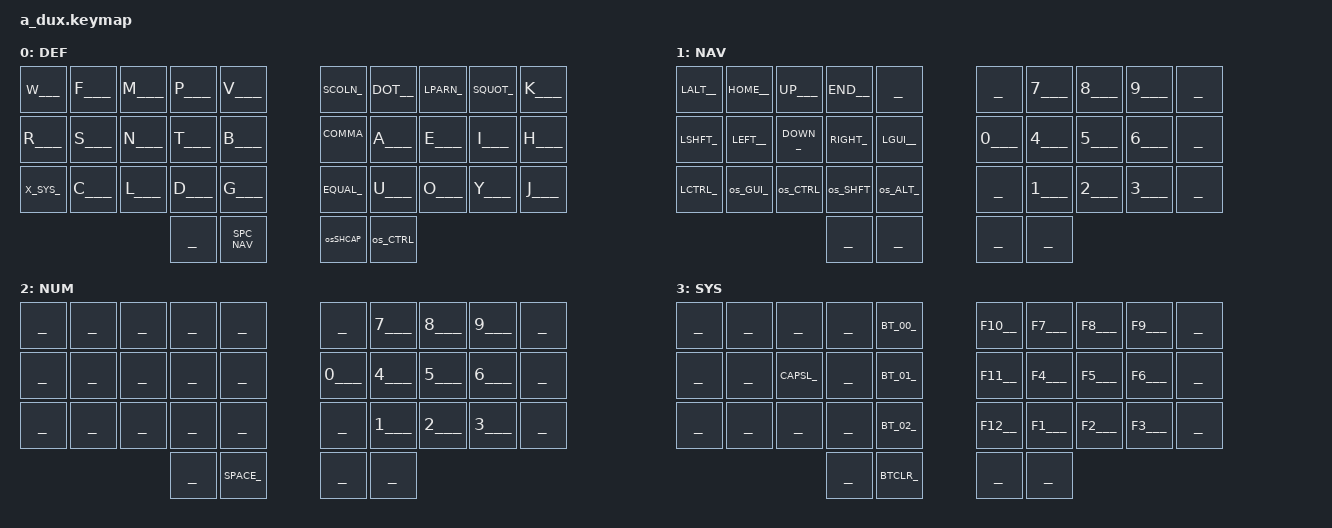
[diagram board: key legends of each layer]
#include <behaviors.dtsi>
#include <dt-bindings/zmk/keys.h>
#include <dt-bindings/zmk/bt.h>
#include "keycodes.h"

// LAYERS
#define DEF 0
#define NAV 1
#define NUM 2
#define SYS 3

#include "macros.dtsi"
#include "combos.dtsi"
#include "mod_morph.dtsi"

&sk {
    // One Shot Mod
    release-after-ms = <6000>;
};
&sl {
    // One Shot Layer
    release-after-ms = <1000>;
};

/ {
    behaviors {
      // Sticky Key with Quick Release
      skq: sticky_key_quick_release {
        compatible = "zmk,behavior-sticky-key";
        label = "STICKY_KEY_QUICK_RELEASE";
        #binding-cells = <1>;
        bindings = <&kp>;
        release-after-ms = <2000>;
        quick-release;
      };

      td_shift_capsword: td_shift_capsword {
            compatible = "zmk,behavior-tap-dance";
            label = "TAP_DANCE_SHIFT_CAPSWORD";
            #binding-cells = <0>;
            tapping-term-ms = <250>;
            bindings = <osqSHFT>, <_CAPWD_>;
        };

      bht: balanced_hold_tap {
          compatible = "zmk,behavior-hold-tap";
          label = "balanced_hold_tap";
          #binding-cells = <2>;
          tapping-term-ms = <200>;    // <---[[moderate duration]]
          quick-tap-ms = <0>;
          flavor = "balanced";
          bindings = <&kp>, <&kp>;
      };

      /*
      // Home Row Mods
      lh_pht: left_hand_positional_hold_tap {
            compatible = "zmk,behavior-hold-tap";
            label = "LEFT_POSITIONAL_HOLD_TAP";
            #binding-cells = <2>;
            flavor = "tap-unless-interrupted";
            tapping-term-ms = <100>;                        // <---[[produces tap if held longer than tapping-term-ms]]
            quick-tap-ms = <200>;
            bindings = <&kp>, <&kp>;
            hold-trigger-key-positions = <5 6 7 8 9 15 16 17 18 19 25 26 27 28 29>;    // <---[[right-hand keys]]
      };
      rh_pht: right_hand_positional_hold_tap {
            compatible = "zmk,behavior-hold-tap";
            label = "RIGHT_POSITIONAL_HOLD_TAP";
            #binding-cells = <2>;
            flavor = "tap-unless-interrupted";
            tapping-term-ms = <100>;                        // <---[[produces tap if held longer than tapping-term-ms]]
            quick-tap-ms = <200>;
            bindings = <&kp>, <&kp>;
            hold-trigger-key-positions = <0 1 2 3 4 10 11 12 13 14 20 21 22 23 24>;    // <---[[left-hand keys]]
      };
      */
    };
};

/ {
  
  keymap {
    
    compatible = "zmk,keymap";

    base_layer {
      label = "DEF";
      bindings = <
        ___W___  ___F___  ___M___  ___P___  ___V___    _SCOLN_  __DOT__  _LPARN_  _SQUOT_  ___K___
        ___R___  ___S___  ___N___  ___T___  ___B___    _COMMA_  ___A___  ___E___  ___I___  ___H___
        _X_SYS_  ___C___  ___L___  ___D___  ___G___    _EQUAL_  ___U___  ___O___  ___Y___  ___J___
                                   _______  SPC_NAV    osSHCAP  os_CTRL  
      >;
    };

    nav_layer {
      label = "NAV";
      bindings = <
        _LALT__  _HOME__  __UP___  __END__  _______    _______  ___7___  ___8___  ___9___  _______    
        _LSHFT_  _LEFT__  _DOWN__  _RIGHT_  _LGUI__    ___0___  ___4___  ___5___  ___6___  _______    
        _LCTRL_  os_GUI_  os_CTRL  os_SHFT  os_ALT_    _______  ___1___  ___2___  ___3___  _______    
                                   _______  _______    _______  _______                 
      >;
    };

    num_layer {
      label = "NUM";
      bindings = <
        _______  _______  _______  _______  _______    _______  ___7___  ___8___  ___9___  _______
        _______  _______  _______  _______  _______    ___0___  ___4___  ___5___  ___6___  _______
        _______  _______  _______  _______  _______    _______  ___1___  ___2___  ___3___  _______
                                   _______  _SPACE_    _______  _______                    
      >;
    };

    sys_layer {
      label = "SYS";
      bindings = <
        _______  _______  _______  _______  _BT_00_    __F10__  __F7___  __F8___  __F9___  _______
        _______  _______  _CAPSL_  _______  _BT_01_    __F11__  __F4___  __F5___  __F6___  _______
        _______  _______  _______  _______  _BT_02_    __F12__  __F1___  __F2___  __F3___  _______
                                   _______  _BTCLR_    _______  _______                    
      >;
    };

  };
};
